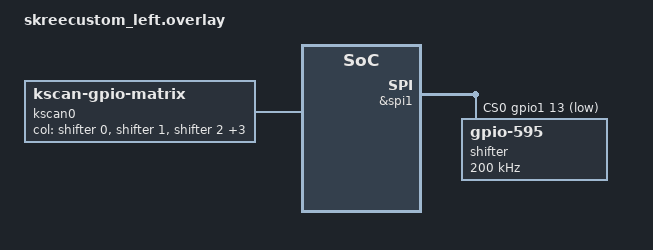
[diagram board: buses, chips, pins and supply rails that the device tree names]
#include "skreecustom.dtsi"

&spi1 {
    status = "okay";
    cs-gpios = <&gpio1 13 GPIO_ACTIVE_LOW>;
    shifter: 595@0 {
        compatible = "zmk,gpio-595";
        status = "okay";
        gpio-controller;
        spi-max-frequency = <200000>;
        reg = <0>;
        #gpio-cells = <2>;
        ngpios = <8>;
    };
};

kscan0: kscan_0 {
    compatible = "zmk,kscan-gpio-matrix";
    diode-direction = "col2row";
    col-gpios
        = <&shifter 0 GPIO_ACTIVE_HIGH>
        , <&shifter 1 GPIO_ACTIVE_HIGH>
        , <&shifter 2 GPIO_ACTIVE_HIGH>
        , <&shifter 3 GPIO_ACTIVE_HIGH>
        , <&shifter 4 GPIO_ACTIVE_HIGH>
        , <&shifter 5 GPIO_ACTIVE_HIGH>
//        , <&shifter 6 GPIO_ACTIVE_HIGH>
//        , <&shifter 7 GPIO_ACTIVE_HIGH>
        ;
};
